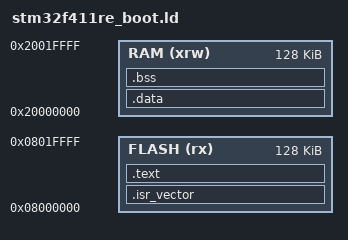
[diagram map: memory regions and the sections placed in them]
/* Minimal linker script for STM32F411RE bootloader
   Places FLASH at 0x08000000 and RAM at 0x20020000 (example).
   Adjust FLASH length and RAM as needed for your device.
*/

ENTRY(Reset_Handler)

MEMORY
{
  FLASH (rx) : ORIGIN = 0x08000000, LENGTH = 128K
  RAM (xrw)  : ORIGIN = 0x20000000, LENGTH = 128K
}

SECTIONS
{
  .isr_vector : {
    KEEP(*(.isr_vector))
  } > FLASH

  .text : {
    *(.text*)
    *(.rodata*)
    KEEP(*(.init))
    KEEP(*(.fini))
  } > FLASH

  .data : AT (ADDR(.text) + SIZEOF(.text)) {
    *(.data*)
  } > RAM

  .bss : {
    *(.bss*)
    *(COMMON)
  } > RAM

  /DISCARD/ : { *(.comment*) }
}
